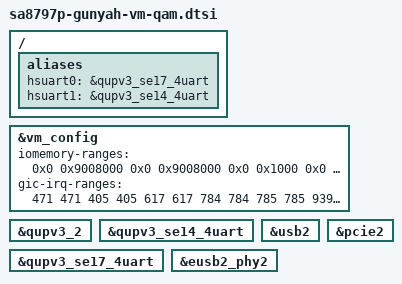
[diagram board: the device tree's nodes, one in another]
// SPDX-License-Identifier: BSD-3-Clause
/*
 * Copyright (c) Qualcomm Technologies, Inc. and/or its subsidiaries.
 */

#include "sa8797p-gunyah-vm.dtsi"
#include "sa8797p-gunyah-vm-qupv3.dtsi"
#include "sa8797p-vm-usb.dtsi"
#include "sa8797p-vm-pcie.dtsi"
#include "sa8797p-pinctrl.dtsi"

/ {
	aliases {
		hsuart0 = &qupv3_se17_4uart;
		hsuart1 = &qupv3_se14_4uart;
	};
};

&vm_config {
	/* Pass through regions */
	iomemory-ranges = <
		/* MPROC NS1 IPCC region */
		0x0 0x9008000 0x0 0x9008000 0x0 0x1000 0x0
		/* QUPv3 Tile 2 read-only region */
		0x0 0x8C0000 0x0 0x8C0000 0x0 0x2000 0x1
		/* QUPv3 SE14 region */
		0x0 0x880000 0x0 0x880000 0x0 0x3000 0x0
		/* QUPv3 SE17 region */
		0x0 0x88C000 0x0 0x88C000 0x0 0x3000 0x0
		/* USB2 region */
		0x0 0x88e0000 0x0 0x88e0000 0x0 0x1000 0x0
		0x0 0xa200000 0x0 0xa200000 0x0 0x200000 0x0
		/* PCIE2 regions */
		0x40 0x0 0x40 0x0 0x0 0x10000000 0x0
		0x0 0x50000000 0x0 0x50000000 0x0 0x100000 0x0
		0x0 0x50100000 0x0 0x50100000 0x0 0x7000000 0x0
		0x40 0x10100000 0x40 0x10100000 0x0 0x100000 0x0
		/* TLMM region */
		0x0 0xF000000 0x0 0xF000000 0x0 0x1000000 0x0
		/* MDSS 0 region */
		0x0 0xAE00000 0x0 0xAE00000 0x0 0x180000 0x1
		/* MDSS 0 LUT DMA CTL region */
		0x0 0x0AF80000 0x0 0x0AF80000 0x0 0x1000 0x1
		/* MDSS 0 LUT DMA VQ region */
		0x0 0x0AF81000 0x0 0x0AF81000 0x0 0x10000 0x0
		/* MDSS 0 VA_TRAN CTL region */
		0x0 0xAFA4000 0x0 0xAFA4000 0x0 0x1000 0x1
		/* MDSS 0 VA_TRAN VQ region */
		0x0 0xAFA5000 0x0 0xAFA5000 0x0 0x10000 0x0
		/* MDSS 1 region */
		0x0 0x8C00000 0x0 0x8C00000 0x0 0x180000 0x1
		/* MDSS 1 LUT DMA CTL region */
		0x0 0x8D80000 0x0 0x8D80000 0x0 0x1000 0x1
		/* MDSS 1 LUT DMA VQ region */
		0x0 0x8D81000 0x0 0x8D81000 0x0 0x10000 0x0
		/* MDSS 1 VA_TRAN CTL region */
		0x0 0x8DA4000 0x0 0x8DA4000 0x0 0x1000 0x1
		/* MDSS 1 VA_TRAN VQ region */
		0x0 0x8DA5000 0x0 0x8DA5000 0x0 0x10000 0x0
		/* QRNG region */
		0x0 0x10cd000 0x0 0x10cd000 0x0 0x1000 0x0
	>;

	/* Pass through IRQs */
	gic-irq-ranges = <
		/* MPROC NS1 IPCC GIC IRQ */
		471 471
		/* QUPv3 SE14 GIC IRQ */
		405 405
		/* QUPv3 SE17 GIC IRQ */
		617 617
		/*USB2 IRQs*/
		784 784
		785 785
		939 939
		942 942
		/* PCIE2 GIC IRQs */
		876 876
		870 870
		145 145
		857 857
		878 878
		382 382
		869 869
		136 136
	>;
};

&qupv3_2 {
	status = "ok";
};

&qupv3_se14_4uart {
	status = "ok";
};

&qupv3_se17_4uart {
	status = "ok";
};

&usb2 {
	status = "ok";
};

&eusb2_phy2 {
	status = "ok";
};

&pcie2 {
	status = "ok";
};
